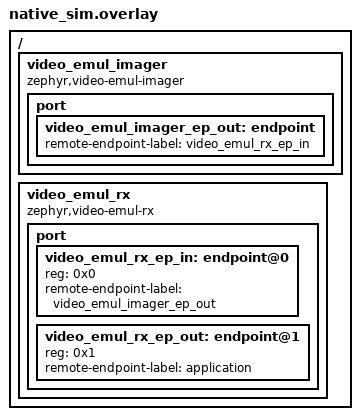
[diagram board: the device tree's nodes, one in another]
/*
 * Copyright (c) 2024 tinyVision.ai Inc.
 *
 * SPDX-License-Identifier: Apache-2.0
 */

/ {
	video_emul_imager: video_emul_imager {
		compatible = "zephyr,video-emul-imager";

		port {
			video_emul_imager_ep_out: endpoint {
				remote-endpoint-label = "video_emul_rx_ep_in";
			};
		};
	};

	video_emul_rx: video_emul_rx {
		compatible = "zephyr,video-emul-rx";

		port {
			#address-cells = <1>;
			#size-cells = <0>;

			video_emul_rx_ep_in: endpoint@0 {
				reg = <0x0>;
				remote-endpoint-label = "video_emul_imager_ep_out";
			};

			video_emul_rx_ep_out: endpoint@1 {
				reg = <0x1>;
				remote-endpoint-label = "application";
			};
		};
	};
};
